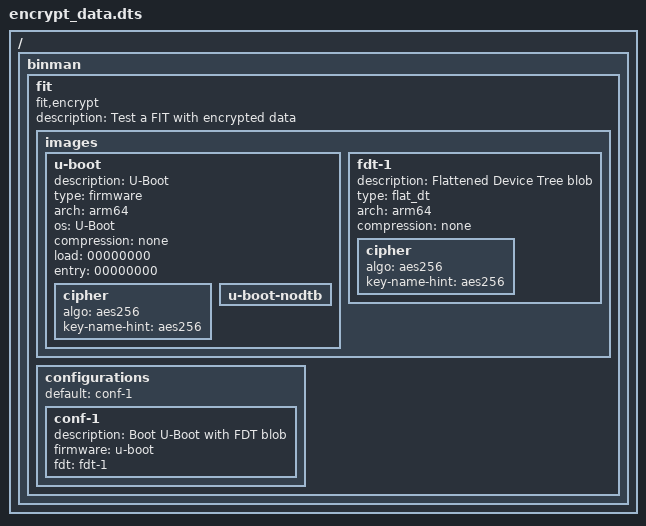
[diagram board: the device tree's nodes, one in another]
// SPDX-License-Identifier: GPL-2.0+

/dts-v1/;

/ {
	#address-cells = <1>;
	#size-cells = <1>;

	binman {
		fit {
			fit,encrypt;
			description = "Test a FIT with encrypted data";
			#address-cells = <1>;

			images {
				u-boot {
					description = "U-Boot";
					type = "firmware";
					arch = "arm64";
					os = "U-Boot";
					compression = "none";
					load = <00000000>;
					entry = <00000000>;
					cipher {
						algo = "aes256";
						key-name-hint = "aes256";
					};
					u-boot-nodtb {
					};
				};
				fdt-1 {
					description = "Flattened Device Tree blob";
					type = "flat_dt";
					arch = "arm64";
					compression = "none";
					cipher {
						algo = "aes256";
						key-name-hint = "aes256";
					};
				};
			};

			configurations {
				default = "conf-1";
				conf-1 {
					description = "Boot U-Boot with FDT blob";
					firmware = "u-boot";
					fdt = "fdt-1";
				};
			};
		};
	};
};
